AUTOSAR XML (schema 4-2-2)
package /Components
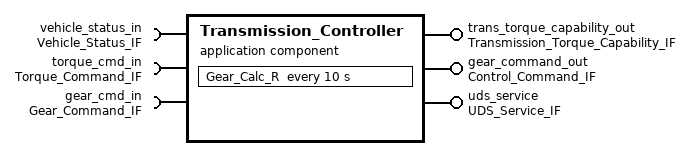
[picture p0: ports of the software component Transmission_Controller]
  application sw component type Transmission_Controller
    provide port trans_torque_capability_out: provided-interface=Transmission_Torque_Capability_IF
    provide port gear_command_out: provided-interface=Control_Command_IF
    provide port uds_service: provided-interface=UDS_Service_IF
    require port vehicle_status_in: required-interface=Vehicle_Status_IF
    require port torque_cmd_in: required-interface=Torque_Command_IF
    require port gear_cmd_in: required-interface=Gear_Command_IF
    behavior Transmission_Controller_InternalBehavior
      data received event Gear_Command_Update: start-on-event=Trans_Apply_R
      init event Trans_Init: start-on-event=Trans_Init_R
      operation invoked event Diag_ReadData_Invoked: start-on-event=Diag_Service_R
      timing event Trans_Periodic_10ms: start-on-event=Gear_Calc_R, period=10
      4 x runnable:
        Trans_Init_R
          parameter access PA_Init_ShiftCalibration: accessed-parameter=torque_cmd_in.trans_torque_cmd_nm
        Gear_Calc_R: minimum-start-interval=10
          data-receive-point-by-arguments:
            access VA_Arg_VehicleSpeed: accessed-variable=vehicle_status_in.vehicle_speed_kph
            access VA_Arg_EngineRpm: accessed-variable=vehicle_status_in.engine_rpm
          data-send-points:
            access VA_Send_TransCapability: accessed-variable=trans_torque_capability_out.trans_torque_capability_nm
        Trans_Apply_R
          data-receive-point-by-values:
            access VA_Val_TransTorqueCmd: accessed-variable=torque_cmd_in.trans_torque_cmd_nm
            access VA_Val_GearCmd: accessed-variable=gear_cmd_in.gear_cmd
          data-send-points:
            access VA_Send_GearCommandOut: accessed-variable=gear_command_out.gear_command_out
        Diag_Service_R: minimum-start-interval=50
